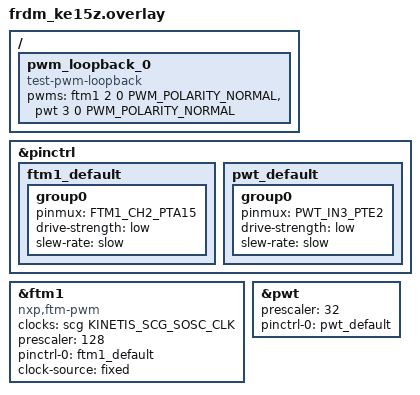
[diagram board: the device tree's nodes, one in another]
/*
 * Copyright 2026 NXP
 *
 * SPDX-License-Identifier: Apache-2.0
 */

/*
 * To test this sample, connect
 * PTA15 (Arduino D10) ---> PTE2 (Arduino D11)
 */

&pinctrl {
	ftm1_default: ftm1_default {
		group0 {
			pinmux = <FTM1_CH2_PTA15>;
			drive-strength = "low";
			slew-rate = "slow";
		};
	};

	pwt_default: pwt_default {
		group0 {
			pinmux = <PWT_IN3_PTE2>;
			drive-strength = "low";
			slew-rate = "slow";
		};
	};
};

/ {
	pwm_loopback_0 {
		compatible = "test-pwm-loopback";
		pwms = <&ftm1 2 0 PWM_POLARITY_NORMAL>, /* PTA15 Arduino D10 */
		       <&pwt 3 0 PWM_POLARITY_NORMAL>;  /* PTE2  Arduino D11 */
	};
};

&ftm1 {
	status = "okay";
	compatible = "nxp,ftm-pwm";
	clocks = <&scg KINETIS_SCG_SOSC_CLK>;
	prescaler = <128>;
	#pwm-cells = <3>;
	pinctrl-0 = <&ftm1_default>;
	pinctrl-names = "default";
	clock-source = "fixed";
};

&pwt {
	status = "okay";
	prescaler = <32>;
	pinctrl-0 = <&pwt_default>;
	pinctrl-names = "default";
};
